VERSION ""

NS_ :

BS_:

BU_: XXX

BO_ 258 STEERING: 8 XXX
 SG_ STEER_ANGLE : 4|13@0+ (0.3187251,-1307.888) [-360|360] "deg" XXX

BO_ 514 SPEED: 8 XXX
 SG_ SPEED : 5|10@0+ (0.07,0) [0|65535] "m/s" XXX

BO_ 653 BRAKE_MODULE: 8 XXX
 SG_ BRAKE_PRESSURE : 15|8@0+ (1,0) [0|255] "" XXX
 SG_ BRAKE_PRESSED : 4|1@0+ (1,0) [0|4] "" XXX

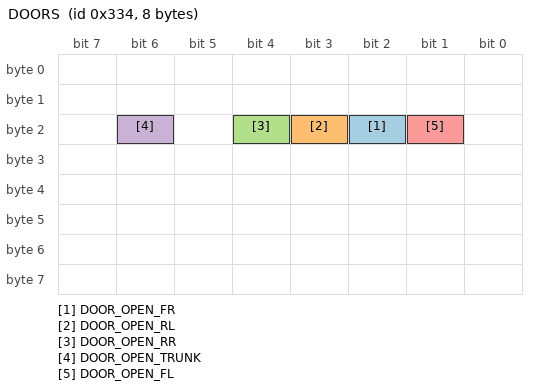
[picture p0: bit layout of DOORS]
BO_ 820 DOORS: 8 XXX
 SG_ DOOR_OPEN_FR : 18|1@0+ (1,0) [0|1] "" XXX
 SG_ DOOR_OPEN_RL : 19|1@0+ (1,0) [0|1] "" XXX
 SG_ DOOR_OPEN_RR : 20|1@0+ (1,0) [0|1] "" XXX
 SG_ DOOR_OPEN_TRUNK : 22|1@0+ (1,0) [0|1] "" XXX
 SG_ DOOR_OPEN_FL : 17|1@0+ (1,0) [0|1] "" XXX

BO_ 746 GEAR: 8 XXX
 SG_ PRNDL : 0|3@1+ (1,0) [0|7] "" XXX

BO_ 792 STEERING_LEVERS: 8 XXX
 SG_ TURN_SIGNALS : 1|2@0+ (1,0) [0|3] "" XXX

CM_ SG_ 258 STEER_ANGLE "positive is left (counter-clockwise)";
CM_ SG_ 514 SPEED "TODO find upper limit";
CM_ SG_ 653 BRAKE_PRESSURE "max seems to be 148";
CM_ SG_ 746 PRNDL "4=D, 3=N, 2=R, 1=P";
CM_ SG_ 792 TURN_SIGNALS "1=Left, 2=Right";
VAL_ 746 PRNDL 4 "Drive" 3 "Neutral" 2 "Reverse" 1 "Park" ;
VAL_ 792 TURN_SIGNALS 2 "Right" 1 "Left" ;
